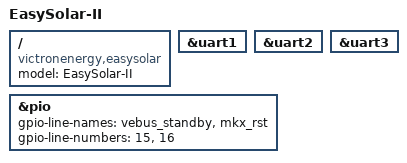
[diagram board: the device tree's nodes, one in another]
// SPDX-License-Identifier: GPL-2.0 OR X11
/*
 * Copyright (C) 2018 Mans Rullgard <mans@mansr.com>
 */

#include "sun8i-h3-nanopi-easysolar-base.dtsi"
#include "victron-character-display.dtsi"

/ {
	model = "EasySolar-II";
	compatible = "victronenergy,easysolar",
		     "friendlyarm,nanopi-neo-core",
		     "allwinner,sun8i-h3";
};

&uart1 {
	status = "okay";
};

&uart2 {
	status = "okay";
};

&uart3 {
	status = "okay";
};

&pio {
	gpio-line-names = "vebus_standby", "mkx_rst";
	gpio-line-numbers = <15>, <16>;
};
